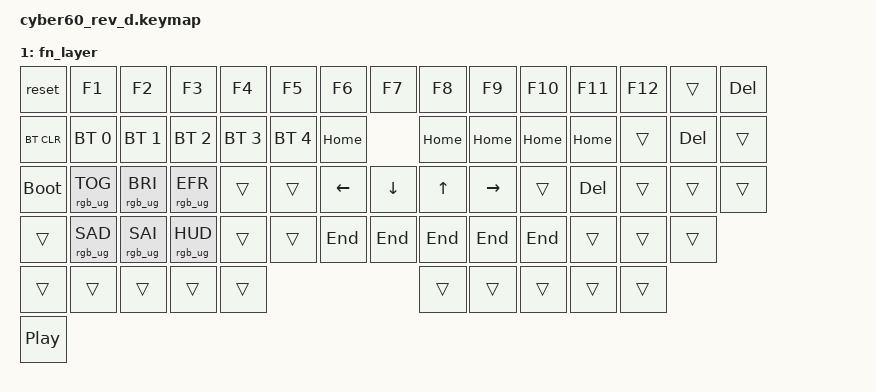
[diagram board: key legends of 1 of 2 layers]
#include <behaviors.dtsi>
#include <dt-bindings/zmk/keys.h>
#include <dt-bindings/zmk/bt.h>
#include <dt-bindings/zmk/outputs.h>
#include <dt-bindings/zmk/rgb.h>
#include <dt-bindings/zmk/ext_power.h>

#define FN1 1
/ {
	keymap {
		compatible = "zmk,keymap";
		base_layer {
// Base layer
// ------------------------------------------------------------------------------------------
// | ESC |  1  |  2  |  3  |  4  |  5  |  6  |  7  |  8  |  9  |  0  |  -  |  =  |   BKSP   |
// |  TAB |  Q  |  W  |  E  |  R  |  T  |  Y  |  U  |  I  |  O  |  P  |  [  |  ]  |   "|"   |
// | CAPS  |  A  |  S  |  D  |  F  |  G  |  H  |  J  |  K  |  L  |  ;  |  '  |NUHS| ENTER   |
// | SHIFT |NUBS| Z |  X  |  C  |  V  |  B  |  N  |  M  |  ,  |  .  |  /  |    Shift   | FN |
// |  LCTL  |  LWIN  |  LALT  | SPACE  | SPACE |    SPACE   |  RALT | FN  |   RWIN  | RCTRL |
// | Rotary | (<-- Rotary switch) ----------------------------------------------------------- 
				bindings = <
	&kp ESC		 &kp NUM_1 	&kp NUM_2	&kp NUM_3 	&kp NUM_4 &kp NUM_5 &kp NUM_6 	&kp NUM_7 	&kp NUM_8 &kp NUM_9	&kp NUM_0	&kp MINUS	&kp EQL  	&none	&kp BKSP
	&kp TAB		 &kp   Q   	&kp   W   	&kp   E   	&kp   R   &kp   T   &kp   Y   	&kp   U   	&kp   I   &kp   O   &kp   P   	&kp LBKT 	&kp RBKT	&none
	&mo FN1		 &kp   A   	&kp   S   	&kp   D   	&kp   F   &kp   G   &kp   H   	&kp   J   	&kp   K   &kp   L   &kp  SEMI  	&kp  SQT   &kp NUHS	 &kp RET
	&kp LSFT 	 &kp NUBS	&kp   Z   	&kp   X   	&kp   C   &kp   V   &kp   B   	&kp   N   	&kp   M   &kp  CMMA &kp  DOT  	&kp  FSLH	&kp RSFT 	&mo FN1
	&kp LCTL 	 &kp LGUI   &kp   LALT				&kp SPC			&mo FN1			&kp  BKSP  			  &kp  RALT &kp  RALT 	&mo  FN1	&kp  RCTL		
	&kp C_PP
			>;
			sensor-bindings = <&inc_dec_kp C_VOL_DN C_VOL_UP>;
		};
				fn_layer {
// Function layer
// ------------------------------------------------------------------------------------------
// | RESET | F1 |  F2 |  F3 |  F4 |  F5 |  F6 |  F7 |  F8 |  F9 | F10 | F11 | F12 |TRNS | DEL |
// |BT_CLR |TRNS | UP  | BT0 | BT1 | BT2 | BT3 | BT4 | TRNS | TRNS | TRNS | TRNS | TRNS | TRNS|
// | BOOTL  |LEFT |DOWN |RIGHT|TRNS |TRNS |TRNS | TRNS| TRNS |TRNS| TRNS |TRNS | TRNS | TRNS  |
// | TRNS |TRNS|TRNS|TRNS|TRNS | TRNS| TRNS | TRNS |  TRNS| TRNS | TRNS| TRNS |   TRNS   |TRNS|
// |  TRNS | TRNS | TRNS |      TRNS      | TRNS |     TRNS     |  TRNS |  TRNS | TRNS | TRNS |
// | Rotary | (<-- Rotary switch) ----------------------------------------------------------- 
			bindings = <
	&reset 			&kp F1			&kp F2 	 		&kp F3			&kp F4			&kp F5		 &kp F6	&kp F7		&kp F8		&kp F9	&kp F10		&kp F11	&kp F12	&trans	&kp DEL
	&bt BT_CLR		&bt BT_SEL 0	&bt BT_SEL 1   	&bt BT_SEL 2  	&bt BT_SEL 3   	&bt BT_SEL 4 &kp HOME &kp HOME	&kp HOME	&kp HOME	&kp HOME     &trans	&kp DEL	&trans	
	&bootloader 	&rgb_ug RGB_TOG &rgb_ug RGB_BRI	&rgb_ug RGB_EFR	&trans		 	&trans		 &kp LEFT	&kp DOWN	&kp UP	&kp RIGHT 	&trans   &kp DEL 	&trans	&trans &trans
	&trans 			&rgb_ug RGB_SAD &rgb_ug RGB_SAI &rgb_ug	RGB_HUD	&trans		 	&trans		 &kp END	&kp END	&kp END	&kp END	&kp END     &trans	&trans 	&trans
	&trans 			&trans   	  	&trans             								&trans		 &trans	&trans  				&trans  &trans	&trans	&trans		
	&kp C_PP
			>;
			sensor-bindings = <&inc_dec_kp C_VOL_DN C_VOL_UP>;
		};
	};
};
